# PIC16LF720 register map
Vendor: Microchip
Registers are 8-bit, read-write, no defined reset value unless marked. A register's access mark holds for its fields unless they carry their own. Addresses are absolute, and some are shared; only a register's first bit layout is shown; [hi:lo] are bit positions; {n}, {i} and the like mark numbered series.

## SFR
0x00 INDF access not given — (power-on value xxxxxxxx)
0x01 TMR0 — (power-on value xxxxxxxx)
0x02 PCL reset 0x0
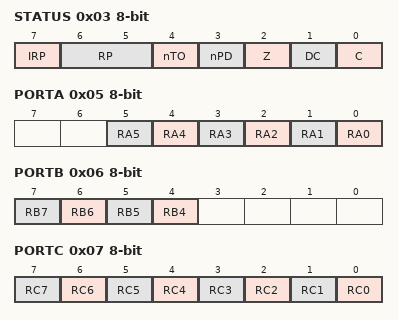
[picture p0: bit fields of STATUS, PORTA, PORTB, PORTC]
0x03 STATUS — (power-on value 00011xxx)
  [7] IRP, [6:5] RP, [4] nTO ro, [3] nPD ro, [2] Z, [1] DC, [0] C
0x04 FSR — (power-on value xxxxxxxx)
0x05 PORTA — (power-on value --xxxxxx)
  [n] RA{n} (n=0..5)
0x06 PORTB — (power-on value xxxx----)
  [n] RB{n} (n=4..7)
0x07 PORTC — (power-on value xxxxxxxx)
  [n] RC{n} (n=0..7)
0x0A PCLATH reset 0x0
  [4:0] PCLATH
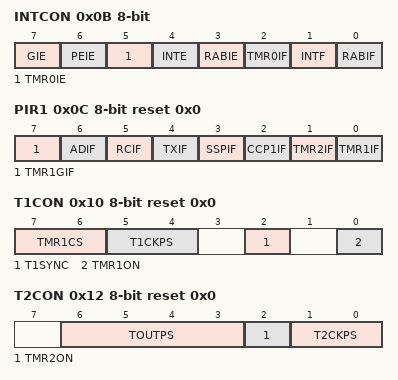
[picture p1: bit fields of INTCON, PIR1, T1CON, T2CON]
0x0B INTCON — (power-on value 0000000x)
  [7] GIE, [6] PEIE, [5] TMR0IE, [4] INTE, [3] RABIE, [2] TMR0IF, [1] INTF, [0] RABIF
0x0C PIR1 reset 0x0
  [7] TMR1GIF, [6] ADIF, [5] RCIF ro, [4] TXIF ro, [3] SSPIF, [2] CCP1IF, [1] TMR2IF, [0] TMR1IF
0x0E TMR1L — (power-on value xxxxxxxx)
0x0F TMR1H — (power-on value xxxxxxxx)
0x10 T1CON reset 0x0
  [7:6] TMR1CS
    2=External Clock source from T1CKI pin on rising edge; 1=Clock source is FOSC; 0=Clock source is FOSC/4 instruction clock
  [5:4] T1CKPS
    3=1:8 prescale; 2=1:4 prescale; 1=1:2 prescale; 0=1:1 prescale
  [2] T1SYNC
    1=Do not synchronize external clock input; 0=Synchronize external clock with system clock
  [0] TMR1ON
    1=Enables Timer1; 0=Disables Timer1
0x11 TMR2 reset 0x0
0x12 T2CON reset 0x0
  [6:3] TOUTPS
    {v}=1:{v+1} (v=0..15)
  [2] TMR2ON
    1=Timer2 on; 0=Timer2 off
  [1:0] T2CKPS
    0=1:1; 1=1:4; 0b1x=1:16
0x13 SSPBUF — (power-on value xxxxxxxx)
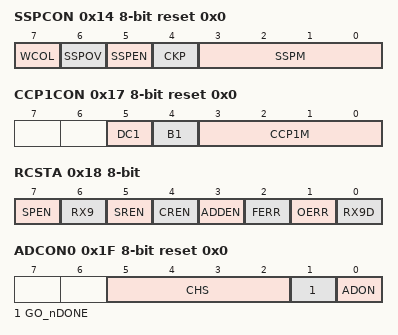
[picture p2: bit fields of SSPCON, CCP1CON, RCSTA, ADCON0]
0x14 SSPCON reset 0x0
  [7] WCOL
    1=SSPBUF is writting while transmitting previous word; 0=No collision
  [6] SSPOV
  [5] SSPEN
    1=Enable; 0=Disable
  [4] CKP
  [3:0] SSPM
    0=FOSC/4; 1=FOSC/16; 2=FOSC/64; 3=TMR2 output/2; 4=SCK pin and nSS pin enabled; 5=SCK pin and nSS pin disabled and nSS used as I/O; 6=I2C slave mode, 7 bit address; 7=I2C slave mode, 10 bit address; 9=Load SSPMSK at SSPADD; 11=I2C master mode, slave IDLE; 14=I2C slave mode 7 bit address w/start-stop interrupts enabled; 15=I2C slave mode 10bit address w/start-stop interrupts disabled
0x15 CCPR1L — (power-on value xxxxxxxx)
0x16 CCPR1H — (power-on value xxxxxxxx)
0x17 CCP1CON reset 0x0
  [5] DC1
  [4] B1
  [3:0] CCP1M
    0=CCP disabled; 2=Compare mode, toggle output on match, CCP1IF is set; 4=Capture mode, every falling edge; 5=Capture mode, every rising edge; 6=Capture mode, every 4th rising edge; 7=Capture mode, every 16th rising edge; 8=Compare mode, set output on match, CCP1IF is set; 9=Compare mode, clear output on match, CCP1IF is set; 10=Compare mode, generate interrupt on match, CCP1IF is set; 11=Compare mode, trigger special event; 0b11xx=PWM mode
0x18 RCSTA — (power-on value 0000000x)
  [7] SPEN, [6] RX9, [5] SREN, [4] CREN, [3] ADDEN, [2] FERR ro, [1] OERR ro, [0] RX9D ro
0x19 TXREG reset 0x0
0x1A RCREG ro reset 0x0
0x1E ADRES — (power-on value xxxxxxxx)
0x1F ADCON0 reset 0x0
  [5:2] CHS, [1] GO_nDONE, [0] ADON
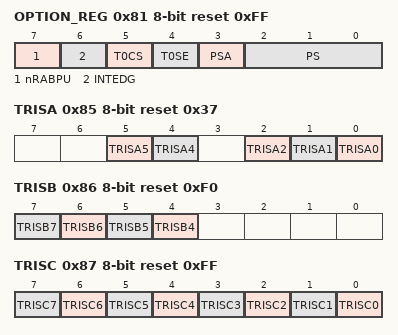
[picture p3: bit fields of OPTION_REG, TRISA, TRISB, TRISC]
0x81 OPTION_REG reset 0xFF
  [7] nRABPU, [6] INTEDG, [5] T0CS, [4] T0SE, [3] PSA, [2:0] PS
0x85 TRISA reset 0x37
  [5] TRISA5, [4] TRISA4, [2] TRISA2, [1] TRISA1, [0] TRISA0
0x86 TRISB reset 0xF0
  [n] TRISB{n} (n=4..7)
0x87 TRISC reset 0xFF
  [n] TRISC{n} (n=0..7)
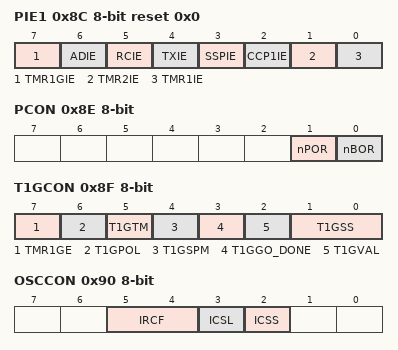
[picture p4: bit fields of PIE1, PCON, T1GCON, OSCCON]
0x8C PIE1 reset 0x0
  [7] TMR1GIE, [6] ADIE, [5] RCIE, [4] TXIE, [3] SSPIE, [2] CCP1IE, [1] TMR2IE, [0] TMR1IE
0x8E PCON — (power-on value ------qq)
  [1] nPOR, [0] nBOR
0x8F T1GCON — (power-on value 00000x00)
  [7] TMR1GE, [6] T1GPOL, [5] T1GTM, [4] T1GSPM, [3] T1GGO_DONE, [2] T1GVAL ro, [1:0] T1GSS
0x90 OSCCON — (power-on value --10qq--)
  [5:4] IRCF, [3] ICSL, [2] ICSS
0x91 OSCTUNE reset 0x0
  [5:0] TUN
0x92 PR2 reset 0xFF
0x93 SSPADD reset 0x0
  [7:0] ADD
0x93 SSPMSK reset 0xFF
  [7:0] MSK
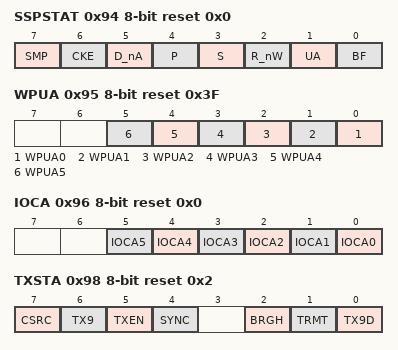
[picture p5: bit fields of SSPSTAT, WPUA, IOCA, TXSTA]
0x94 SSPSTAT reset 0x0
  [7] SMP, [6] CKE, [5] D_nA, [4] P, [3] S, [2] R_nW, [1] UA, [0] BF
0x95 WPUA reset 0x3F
  [n] WPUA{n} (n=0..5)
0x96 IOCA reset 0x0
  [n] IOCA{n} (n=0..5)
0x98 TXSTA reset 0x2
  [7] CSRC, [6] TX9, [5] TXEN, [4] SYNC, [2] BRGH, [1] TRMT ro, [0] TX9D
0x99 SPBRG reset 0x0
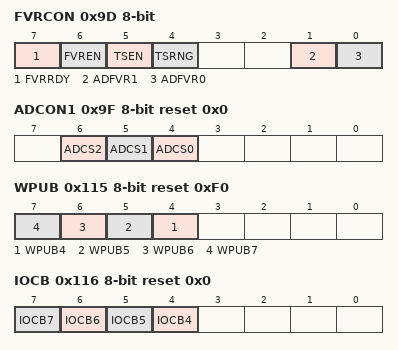
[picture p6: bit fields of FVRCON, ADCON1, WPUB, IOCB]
0x9D FVRCON — (power-on value q0xx--00)
  [7] FVRRDY, [6] FVREN, [5] TSEN, [4] TSRNG, [1] ADFVR1, [0] ADFVR0
0x9F ADCON1 reset 0x0
  [6] ADCS2, [5] ADCS1, [4] ADCS0
0x10C PMDATL — (power-on value xxxxxxxx)
0x10D PMADRL reset 0x0
0x10E PMDATH — (power-on value --xxxxxx)
  [5:0] PMDATH
0x10F PMADRH reset 0x0
  [4:0] PMADRH
0x115 WPUB reset 0xF0
  [n] WPUB{n} (n=4..7)
0x116 IOCB reset 0x0
  [n] IOCB{n} (n=4..7)
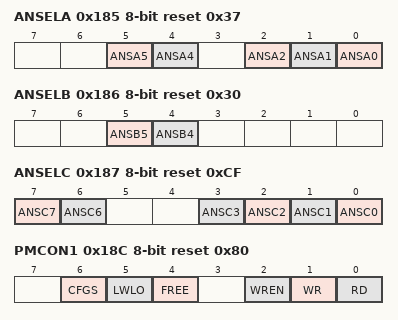
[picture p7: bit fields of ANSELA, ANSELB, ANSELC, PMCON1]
0x185 ANSELA reset 0x37
  [5] ANSA5, [4] ANSA4, [2] ANSA2, [1] ANSA1, [0] ANSA0
0x186 ANSELB reset 0x30
  [5] ANSB5, [4] ANSB4
0x187 ANSELC reset 0xCF
  [7] ANSC7, [6] ANSC6, [n] ANSC{n} (n=0..3)
0x18C PMCON1 reset 0x80
  [6] CFGS, [5] LWLO, [4] FREE, [2] WREN, [1] WR, [0] RD
0x18D PMCON2 access not given
